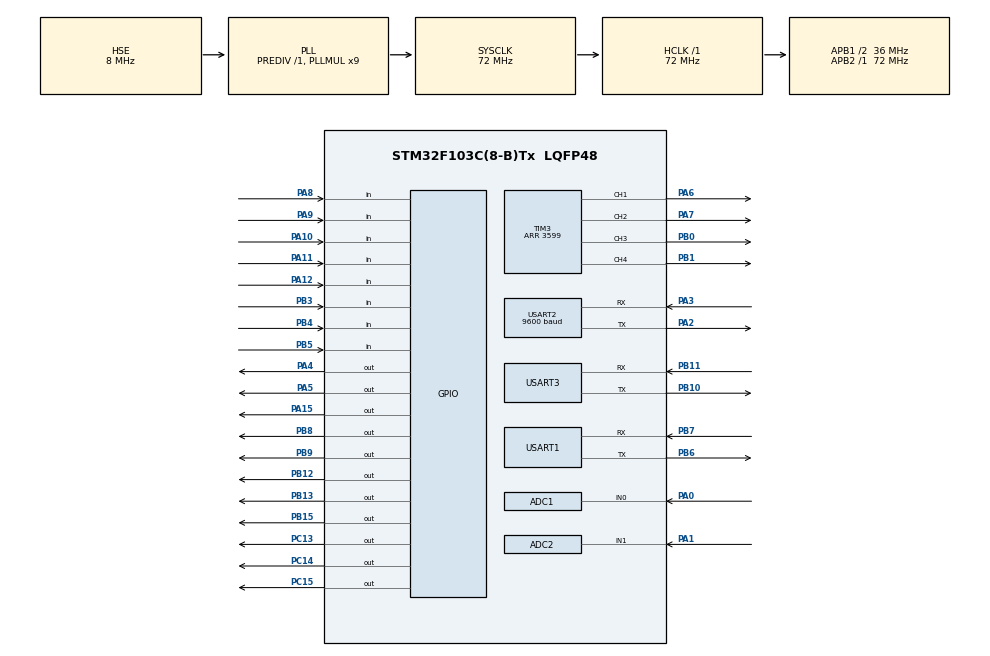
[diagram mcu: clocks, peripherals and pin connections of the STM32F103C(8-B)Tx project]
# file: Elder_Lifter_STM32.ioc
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ADC1.Channel-1\#ChannelRegularConversion=ADC_CHANNEL_0
ADC1.ContinuousConvMode=ENABLE
ADC1.NbrOfConversionFlag=1
ADC1.Rank-1\#ChannelRegularConversion=1
ADC1.SamplingTime-1\#ChannelRegularConversion=ADC_SAMPLETIME_1CYCLE_5
ADC1.master=1
ADC2.Channel-1\#ChannelRegularConversion=ADC_CHANNEL_1
ADC2.ContinuousConvMode=ENABLE
ADC2.NbrOfConversionFlag=1
ADC2.Rank-1\#ChannelRegularConversion=1
ADC2.SamplingTime-1\#ChannelRegularConversion=ADC_SAMPLETIME_1CYCLE_5
Dma.Request0=USART2_RX
Dma.Request1=USART2_TX
Dma.Request2=USART3_RX
Dma.Request3=USART1_RX
Dma.Request4=USART1_TX
Dma.Request5=USART3_TX
Dma.USART1_RX.3.Direction=DMA_PERIPH_TO_MEMORY
Dma.USART1_RX.3.Instance=DMA1_Channel5
Dma.USART1_RX.3.MemDataAlignment=DMA_MDATAALIGN_BYTE
Dma.USART1_RX.3.MemInc=DMA_MINC_ENABLE
Dma.USART1_RX.3.Mode=DMA_NORMAL
Dma.USART1_RX.3.PeriphDataAlignment=DMA_PDATAALIGN_BYTE
Dma.USART1_RX.3.PeriphInc=DMA_PINC_DISABLE
Dma.USART1_RX.3.Priority=DMA_PRIORITY_LOW
Dma.USART1_TX.4.Direction=DMA_MEMORY_TO_PERIPH
Dma.USART1_TX.4.Instance=DMA1_Channel4
Dma.USART1_TX.4.MemDataAlignment=DMA_MDATAALIGN_BYTE
Dma.USART1_TX.4.MemInc=DMA_MINC_ENABLE
Dma.USART1_TX.4.Mode=DMA_NORMAL
Dma.USART1_TX.4.PeriphDataAlignment=DMA_PDATAALIGN_BYTE
Dma.USART1_TX.4.PeriphInc=DMA_PINC_DISABLE
Dma.USART1_TX.4.Priority=DMA_PRIORITY_LOW
Dma.USART2_RX.0.Direction=DMA_PERIPH_TO_MEMORY
Dma.USART2_RX.0.Instance=DMA1_Channel6
Dma.USART2_RX.0.MemDataAlignment=DMA_MDATAALIGN_BYTE
Dma.USART2_RX.0.MemInc=DMA_MINC_ENABLE
Dma.USART2_RX.0.Mode=DMA_NORMAL
Dma.USART2_RX.0.PeriphDataAlignment=DMA_PDATAALIGN_BYTE
Dma.USART2_RX.0.PeriphInc=DMA_PINC_DISABLE
Dma.USART2_RX.0.Priority=DMA_PRIORITY_LOW
Dma.USART2_TX.1.Direction=DMA_MEMORY_TO_PERIPH
Dma.USART2_TX.1.Instance=DMA1_Channel7
Dma.USART2_TX.1.MemDataAlignment=DMA_MDATAALIGN_BYTE
Dma.USART2_TX.1.MemInc=DMA_MINC_ENABLE
Dma.USART2_TX.1.Mode=DMA_NORMAL
Dma.USART2_TX.1.PeriphDataAlignment=DMA_PDATAALIGN_BYTE
Dma.USART2_TX.1.PeriphInc=DMA_PINC_DISABLE
Dma.USART2_TX.1.Priority=DMA_PRIORITY_LOW
Dma.USART3_RX.2.Direction=DMA_PERIPH_TO_MEMORY
Dma.USART3_RX.2.Instance=DMA1_Channel3
Dma.USART3_RX.2.MemDataAlignment=DMA_MDATAALIGN_BYTE
Dma.USART3_RX.2.MemInc=DMA_MINC_ENABLE
Dma.USART3_RX.2.Mode=DMA_NORMAL
Dma.USART3_RX.2.PeriphDataAlignment=DMA_PDATAALIGN_BYTE
Dma.USART3_RX.2.PeriphInc=DMA_PINC_DISABLE
Dma.USART3_RX.2.Priority=DMA_PRIORITY_LOW
Dma.USART3_TX.5.Direction=DMA_MEMORY_TO_PERIPH
Dma.USART3_TX.5.Instance=DMA1_Channel2
Dma.USART3_TX.5.MemDataAlignment=DMA_MDATAALIGN_BYTE
Dma.USART3_TX.5.MemInc=DMA_MINC_ENABLE
Dma.USART3_TX.5.Mode=DMA_NORMAL
Dma.USART3_TX.5.PeriphDataAlignment=DMA_PDATAALIGN_BYTE
Dma.USART3_TX.5.PeriphInc=DMA_PINC_DISABLE
Dma.USART3_TX.5.Priority=DMA_PRIORITY_LOW
Mcu.Family=STM32F1
Mcu.Name=STM32F103C(8-B)Tx
Mcu.Package=LQFP48
NVIC.ADC1_2_IRQn=true\:0\:0\:false\:false\:true\:true\:true\:true
NVIC.DMA1_Channel2_IRQn=true\:0\:0\:false\:false\:true\:false\:true\:true
NVIC.DMA1_Channel3_IRQn=true\:0\:0\:false\:false\:true\:false\:true\:true
NVIC.DMA1_Channel4_IRQn=true\:0\:0\:false\:false\:true\:false\:true\:true
NVIC.DMA1_Channel5_IRQn=true\:0\:0\:false\:false\:true\:false\:true\:true
NVIC.DMA1_Channel6_IRQn=true\:0\:0\:false\:false\:true\:false\:true\:true
NVIC.DMA1_Channel7_IRQn=true\:0\:0\:false\:false\:true\:false\:true\:true
NVIC.PriorityGroup=NVIC_PRIORITYGROUP_4
NVIC.TIM2_IRQn=true\:0\:0\:false\:false\:true\:true\:true\:true
NVIC.USART1_IRQn=true\:0\:0\:false\:false\:true\:true\:true\:true
NVIC.USART2_IRQn=true\:0\:0\:false\:false\:true\:true\:true\:true
NVIC.USART3_IRQn=true\:0\:0\:false\:false\:true\:true\:true\:true
PA0-WKUP.Signal=ADCx_IN0
PA1.Signal=ADCx_IN1
PA10.GPIO_PuPd=GPIO_PULLUP
PA10.Signal=GPIO_Input
PA11.GPIO_PuPd=GPIO_PULLUP
PA11.Signal=GPIO_Input
PA12.GPIO_PuPd=GPIO_PULLUP
PA12.Signal=GPIO_Input
PA13.Mode=Serial_Wire
PA13.Signal=SYS_JTMS-SWDIO
PA14.Mode=Serial_Wire
PA14.Signal=SYS_JTCK-SWCLK
PA15.Signal=GPIO_Output
PA2.Mode=Asynchronous
PA2.Signal=USART2_TX
PA3.Mode=Asynchronous
PA3.Signal=USART2_RX
PA4.Signal=GPIO_Output
PA5.Signal=GPIO_Output
PA6.Signal=S_TIM3_CH1
PA7.Signal=S_TIM3_CH2
PA8.GPIO_PuPd=GPIO_PULLUP
PA8.Signal=GPIO_Input
PA9.GPIO_PuPd=GPIO_PULLUP
PA9.Signal=GPIO_Input
PB0.Signal=S_TIM3_CH3
PB1.Signal=S_TIM3_CH4
PB10.Mode=Asynchronous
PB10.Signal=USART3_TX
PB11.Mode=Asynchronous
PB11.Signal=USART3_RX
PB12.Signal=GPIO_Output
PB13.Signal=GPIO_Output
PB15.Signal=GPIO_Output
PB3.GPIO_PuPd=GPIO_PULLUP
PB3.Signal=GPIO_Input
PB4.GPIO_PuPd=GPIO_PULLUP
PB4.Signal=GPIO_Input
PB5.GPIO_PuPd=GPIO_PULLUP
PB5.Signal=GPIO_Input
PB6.Mode=Asynchronous
PB6.Signal=USART1_TX
PB7.Mode=Asynchronous
PB7.Signal=USART1_RX
PB8.Signal=GPIO_Output
PB9.Signal=GPIO_Output
PC13-TAMPER-RTC.Signal=GPIO_Output
PC14-OSC32_IN.Signal=GPIO_Output
PC15-OSC32_OUT.Signal=GPIO_Output
PD0-OSC_IN.Mode=HSE-External-Oscillator
PD0-OSC_IN.Signal=RCC_OSC_IN
PD1-OSC_OUT.Mode=HSE-External-Oscillator
PD1-OSC_OUT.Signal=RCC_OSC_OUT
ProjectManager.HeapSize=0x200
ProjectManager.StackSize=0x400
ProjectManager.TargetToolchain=STM32CubeIDE
RCC.AHBFreq_Value=72000000
RCC.APB1CLKDivider=RCC_HCLK_DIV2
RCC.APB1Freq_Value=36000000
RCC.APB1TimFreq_Value=72000000
RCC.APB2Freq_Value=72000000
RCC.APB2TimFreq_Value=72000000
RCC.HCLKFreq_Value=72000000
RCC.PLLMUL=RCC_PLL_MUL9
RCC.PLLSourceVirtual=RCC_PLLSOURCE_HSE
RCC.SYSCLKFreq_VALUE=72000000
RCC.SYSCLKSource=RCC_SYSCLKSOURCE_PLLCLK
RCC.USBFreq_Value=48000000
RCC.USBPrescaler=RCC_USBCLKSOURCE_PLL_DIV1_5
SH.ADCx_IN0.0=ADC1_IN0,IN0
SH.ADCx_IN1.0=ADC2_IN1,IN1
SH.ADCx_IN1.1=ADC1_IN1
SH.S_TIM3_CH1.0=TIM3_CH1,PWM Generation1 CH1
SH.S_TIM3_CH2.0=TIM3_CH2,PWM Generation2 CH2
SH.S_TIM3_CH3.0=TIM3_CH3,PWM Generation3 CH3
SH.S_TIM3_CH4.0=TIM3_CH4,PWM Generation4 CH4
TIM2.AutoReloadPreload=TIM_AUTORELOAD_PRELOAD_ENABLE
TIM2.Period=3600
TIM2.Prescaler=1000
TIM3.AutoReloadPreload=TIM_AUTORELOAD_PRELOAD_ENABLE
TIM3.Channel-PWM\ Generation1\ CH1=TIM_CHANNEL_1
TIM3.Channel-PWM\ Generation2\ CH2=TIM_CHANNEL_2
TIM3.Channel-PWM\ Generation3\ CH3=TIM_CHANNEL_3
TIM3.Channel-PWM\ Generation4\ CH4=TIM_CHANNEL_4
TIM3.Period=3599
USART1.VirtualMode=VM_ASYNC
USART2.BaudRate=9600
USART2.VirtualMode=VM_ASYNC
USART3.VirtualMode=VM_ASYNC
VP_TIM2_VS_ClockSourceINT.Mode=Internal
board=custom

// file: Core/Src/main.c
/* USER CODE BEGIN Header */
/**
  ******************************************************************************
  * @file           : main.c
  * @brief          : Main program body
  ******************************************************************************
  * @attention
  *
  * Copyright (c) 2024 STMicroelectronics.
  * All rights reserved.
  *
  * This software is licensed under terms that can be found in the LICENSE file
  * in the root directory of this software component.
  * If no LICENSE file comes with this software, it is provided AS-IS.
  *
  ******************************************************************************
  */
/* USER CODE END Header */
#include "main.h"

/* USER CODE BEGIN Includes */
#include "Lifter_Main.h"
/* USER CODE END Includes */

ADC_HandleTypeDef hadc1;
ADC_HandleTypeDef hadc2;

TIM_HandleTypeDef htim2;
TIM_HandleTypeDef htim3;

UART_HandleTypeDef huart1;
UART_HandleTypeDef huart2;
UART_HandleTypeDef huart3;
DMA_HandleTypeDef hdma_usart1_rx;
DMA_HandleTypeDef hdma_usart1_tx;
DMA_HandleTypeDef hdma_usart2_rx;
DMA_HandleTypeDef hdma_usart2_tx;
DMA_HandleTypeDef hdma_usart3_rx;
DMA_HandleTypeDef hdma_usart3_tx;

void SystemClock_Config(void);
static void MX_GPIO_Init(void);
static void MX_DMA_Init(void);
static void MX_USART2_UART_Init(void);
static void MX_TIM2_Init(void);
static void MX_TIM3_Init(void);
static void MX_USART3_UART_Init(void);
static void MX_USART1_UART_Init(void);
static void MX_ADC1_Init(void);
static void MX_ADC2_Init(void);

int main(void)
{

  /* MCU Configuration--------------------------------------------------------*/

  /* Reset of all peripherals, Initializes the Flash interface and the Systick. */
  HAL_Init();

  /* Configure the system clock */
  SystemClock_Config();

  /* Initialize all configured peripherals */
  MX_GPIO_Init();
  MX_DMA_Init();
  MX_USART2_UART_Init();
  MX_TIM2_Init();
  MX_TIM3_Init();
  MX_USART3_UART_Init();
  MX_USART1_UART_Init();
  MX_ADC1_Init();
  MX_ADC2_Init();
  /* USER CODE BEGIN 2 */
  Lifter_Init();
  /* USER CODE END 2 */

  /* Infinite loop */
  while (1)
  {

    /* USER CODE BEGIN 3 */
	Lifter_Main();
  }
  /* USER CODE END 3 */
}

void SystemClock_Config(void)
{
  RCC_OscInitTypeDef RCC_OscInitStruct = {0};
  RCC_ClkInitTypeDef RCC_ClkInitStruct = {0};
  RCC_PeriphCLKInitTypeDef PeriphClkInit = {0};

  /** Initializes the RCC Oscillators according to the specified parameters
  * in the RCC_OscInitTypeDef structure.
  */
  RCC_OscInitStruct.OscillatorType = RCC_OSCILLATORTYPE_HSE;
  RCC_OscInitStruct.HSEState = RCC_HSE_ON;
  RCC_OscInitStruct.HSEPredivValue = RCC_HSE_PREDIV_DIV1;
  RCC_OscInitStruct.HSIState = RCC_HSI_ON;
  RCC_OscInitStruct.PLL.PLLState = RCC_PLL_ON;
  RCC_OscInitStruct.PLL.PLLSource = RCC_PLLSOURCE_HSE;
  RCC_OscInitStruct.PLL.PLLMUL = RCC_PLL_MUL9;
  if (HAL_RCC_OscConfig(&RCC_OscInitStruct) != HAL_OK)
  {
    Error_Handler();
  }

  /** Initializes the CPU, AHB and APB buses clocks
  */
  RCC_ClkInitStruct.ClockType = RCC_CLOCKTYPE_HCLK|RCC_CLOCKTYPE_SYSCLK
                              |RCC_CLOCKTYPE_PCLK1|RCC_CLOCKTYPE_PCLK2;
  RCC_ClkInitStruct.SYSCLKSource = RCC_SYSCLKSOURCE_PLLCLK;
  RCC_ClkInitStruct.AHBCLKDivider = RCC_SYSCLK_DIV1;
  RCC_ClkInitStruct.APB1CLKDivider = RCC_HCLK_DIV2;
  RCC_ClkInitStruct.APB2CLKDivider = RCC_HCLK_DIV1;

  if (HAL_RCC_ClockConfig(&RCC_ClkInitStruct, FLASH_LATENCY_2) != HAL_OK)
  {
    Error_Handler();
  }
  PeriphClkInit.PeriphClockSelection = RCC_PERIPHCLK_ADC;
  PeriphClkInit.AdcClockSelection = RCC_ADCPCLK2_DIV2;
  if (HAL_RCCEx_PeriphCLKConfig(&PeriphClkInit) != HAL_OK)
  {
    Error_Handler();
  }
}

static void MX_ADC1_Init(void)
{

  ADC_ChannelConfTypeDef sConfig = {0};

  /** Common config
  */
  hadc1.Instance = ADC1;
  hadc1.Init.ScanConvMode = ADC_SCAN_DISABLE;
  hadc1.Init.ContinuousConvMode = ENABLE;
  hadc1.Init.DiscontinuousConvMode = DISABLE;
  hadc1.Init.ExternalTrigConv = ADC_SOFTWARE_START;
  hadc1.Init.DataAlign = ADC_DATAALIGN_RIGHT;
  hadc1.Init.NbrOfConversion = 1;
  if (HAL_ADC_Init(&hadc1) != HAL_OK)
  {
    Error_Handler();
  }

  /** Configure Regular Channel
  */
  sConfig.Channel = ADC_CHANNEL_0;
  sConfig.Rank = ADC_REGULAR_RANK_1;
  sConfig.SamplingTime = ADC_SAMPLETIME_1CYCLE_5;
  if (HAL_ADC_ConfigChannel(&hadc1, &sConfig) != HAL_OK)
  {
    Error_Handler();
  }

}

static void MX_ADC2_Init(void)
{

  ADC_ChannelConfTypeDef sConfig = {0};

  /** Common config
  */
  hadc2.Instance = ADC2;
  hadc2.Init.ScanConvMode = ADC_SCAN_DISABLE;
  hadc2.Init.ContinuousConvMode = ENABLE;
  hadc2.Init.DiscontinuousConvMode = DISABLE;
  hadc2.Init.ExternalTrigConv = ADC_SOFTWARE_START;
  hadc2.Init.DataAlign = ADC_DATAALIGN_RIGHT;
  hadc2.Init.NbrOfConversion = 1;
  if (HAL_ADC_Init(&hadc2) != HAL_OK)
  {
    Error_Handler();
  }

  /** Configure Regular Channel
  */
  sConfig.Channel = ADC_CHANNEL_1;
  sConfig.Rank = ADC_REGULAR_RANK_1;
  sConfig.SamplingTime = ADC_SAMPLETIME_1CYCLE_5;
  if (HAL_ADC_ConfigChannel(&hadc2, &sConfig) != HAL_OK)
  {
    Error_Handler();
  }

}

static void MX_TIM2_Init(void)
{

  TIM_ClockConfigTypeDef sClockSourceConfig = {0};
  TIM_MasterConfigTypeDef sMasterConfig = {0};

  htim2.Instance = TIM2;
  htim2.Init.Prescaler = 1000;
  htim2.Init.CounterMode = TIM_COUNTERMODE_UP;
  htim2.Init.Period = 3600;
  htim2.Init.ClockDivision = TIM_CLOCKDIVISION_DIV1;
  htim2.Init.AutoReloadPreload = TIM_AUTORELOAD_PRELOAD_ENABLE;
  if (HAL_TIM_Base_Init(&htim2) != HAL_OK)
  {
    Error_Handler();
  }
  sClockSourceConfig.ClockSource = TIM_CLOCKSOURCE_INTERNAL;
  if (HAL_TIM_ConfigClockSource(&htim2, &sClockSourceConfig) != HAL_OK)
  {
    Error_Handler();
  }
  sMasterConfig.MasterOutputTrigger = TIM_TRGO_RESET;
  sMasterConfig.MasterSlaveMode = TIM_MASTERSLAVEMODE_DISABLE;
  if (HAL_TIMEx_MasterConfigSynchronization(&htim2, &sMasterConfig) != HAL_OK)
  {
    Error_Handler();
  }

}

static void MX_TIM3_Init(void)
{

  TIM_MasterConfigTypeDef sMasterConfig = {0};
  TIM_OC_InitTypeDef sConfigOC = {0};

  htim3.Instance = TIM3;
  htim3.Init.Prescaler = 0;
  htim3.Init.CounterMode = TIM_COUNTERMODE_UP;
  htim3.Init.Period = 3599;
  htim3.Init.ClockDivision = TIM_CLOCKDIVISION_DIV1;
  htim3.Init.AutoReloadPreload = TIM_AUTORELOAD_PRELOAD_ENABLE;
  if (HAL_TIM_PWM_Init(&htim3) != HAL_OK)
  {
    Error_Handler();
  }
  sMasterConfig.MasterOutputTrigger = TIM_TRGO_RESET;
  sMasterConfig.MasterSlaveMode = TIM_MASTERSLAVEMODE_DISABLE;
  if (HAL_TIMEx_MasterConfigSynchronization(&htim3, &sMasterConfig) != HAL_OK)
  {
    Error_Handler();
  }
  sConfigOC.OCMode = TIM_OCMODE_PWM1;
  sConfigOC.Pulse = 0;
  sConfigOC.OCPolarity = TIM_OCPOLARITY_HIGH;
  sConfigOC.OCFastMode = TIM_OCFAST_DISABLE;
  if (HAL_TIM_PWM_ConfigChannel(&htim3, &sConfigOC, TIM_CHANNEL_1) != HAL_OK)
  {
    Error_Handler();
  }
  if (HAL_TIM_PWM_ConfigChannel(&htim3, &sConfigOC, TIM_CHANNEL_2) != HAL_OK)
  {
    Error_Handler();
  }
  if (HAL_TIM_PWM_ConfigChannel(&htim3, &sConfigOC, TIM_CHANNEL_3) != HAL_OK)
  {
    Error_Handler();
  }
  if (HAL_TIM_PWM_ConfigChannel(&htim3, &sConfigOC, TIM_CHANNEL_4) != HAL_OK)
  {
    Error_Handler();
  }
  HAL_TIM_MspPostInit(&htim3);

}

static void MX_USART1_UART_Init(void)
{

  huart1.Instance = USART1;
  huart1.Init.BaudRate = 115200;
  huart1.Init.WordLength = UART_WORDLENGTH_8B;
  huart1.Init.StopBits = UART_STOPBITS_1;
  huart1.Init.Parity = UART_PARITY_NONE;
  huart1.Init.Mode = UART_MODE_TX_RX;
  huart1.Init.HwFlowCtl = UART_HWCONTROL_NONE;
  huart1.Init.OverSampling = UART_OVERSAMPLING_16;
  if (HAL_UART_Init(&huart1) != HAL_OK)
  {
    Error_Handler();
  }

}

static void MX_USART2_UART_Init(void)
{

  huart2.Instance = USART2;
  huart2.Init.BaudRate = 9600;
  huart2.Init.WordLength = UART_WORDLENGTH_8B;
  huart2.Init.StopBits = UART_STOPBITS_1;
  huart2.Init.Parity = UART_PARITY_NONE;
  huart2.Init.Mode = UART_MODE_TX_RX;
  huart2.Init.HwFlowCtl = UART_HWCONTROL_NONE;
  huart2.Init.OverSampling = UART_OVERSAMPLING_16;
  if (HAL_UART_Init(&huart2) != HAL_OK)
  {
    Error_Handler();
  }

}

static void MX_USART3_UART_Init(void)
{

  huart3.Instance = USART3;
  huart3.Init.BaudRate = 115200;
  huart3.Init.WordLength = UART_WORDLENGTH_8B;
  huart3.Init.StopBits = UART_STOPBITS_1;
  huart3.Init.Parity = UART_PARITY_NONE;
  huart3.Init.Mode = UART_MODE_TX_RX;
  huart3.Init.HwFlowCtl = UART_HWCONTROL_NONE;
  huart3.Init.OverSampling = UART_OVERSAMPLING_16;
  if (HAL_UART_Init(&huart3) != HAL_OK)
  {
    Error_Handler();
  }

}

static void MX_DMA_Init(void)
{

  /* DMA controller clock enable */
  __HAL_RCC_DMA1_CLK_ENABLE();

  /* DMA interrupt init */
  /* DMA1_Channel2_IRQn interrupt configuration */
  HAL_NVIC_SetPriority(DMA1_Channel2_IRQn, 0, 0);
  HAL_NVIC_EnableIRQ(DMA1_Channel2_IRQn);
  /* DMA1_Channel3_IRQn interrupt configuration */
  HAL_NVIC_SetPriority(DMA1_Channel3_IRQn, 0, 0);
  HAL_NVIC_EnableIRQ(DMA1_Channel3_IRQn);
  /* DMA1_Channel4_IRQn interrupt configuration */
  HAL_NVIC_SetPriority(DMA1_Channel4_IRQn, 0, 0);
  HAL_NVIC_EnableIRQ(DMA1_Channel4_IRQn);
  /* DMA1_Channel5_IRQn interrupt configuration */
  HAL_NVIC_SetPriority(DMA1_Channel5_IRQn, 0, 0);
  HAL_NVIC_EnableIRQ(DMA1_Channel5_IRQn);
  /* DMA1_Channel6_IRQn interrupt configuration */
  HAL_NVIC_SetPriority(DMA1_Channel6_IRQn, 0, 0);
  HAL_NVIC_EnableIRQ(DMA1_Channel6_IRQn);
  /* DMA1_Channel7_IRQn interrupt configuration */
  HAL_NVIC_SetPriority(DMA1_Channel7_IRQn, 0, 0);
  HAL_NVIC_EnableIRQ(DMA1_Channel7_IRQn);

}

static void MX_GPIO_Init(void)
{
  GPIO_InitTypeDef GPIO_InitStruct = {0};

  /* GPIO Ports Clock Enable */
  __HAL_RCC_GPIOC_CLK_ENABLE();
  __HAL_RCC_GPIOD_CLK_ENABLE();
  __HAL_RCC_GPIOA_CLK_ENABLE();
  __HAL_RCC_GPIOB_CLK_ENABLE();

  /*Configure GPIO pin Output Level */
  HAL_GPIO_WritePin(GPIOC, GPIO_PIN_13|GPIO_PIN_14|GPIO_PIN_15, GPIO_PIN_RESET);

  /*Configure GPIO pin Output Level */
  HAL_GPIO_WritePin(GPIOA, GPIO_PIN_4|GPIO_PIN_5|GPIO_PIN_15, GPIO_PIN_RESET);

  /*Configure GPIO pin Output Level */
  HAL_GPIO_WritePin(GPIOB, GPIO_PIN_12|GPIO_PIN_13|GPIO_PIN_15|GPIO_PIN_8
                          |GPIO_PIN_9, GPIO_PIN_RESET);

  /*Configure GPIO pins : PC13 PC14 PC15 */
  GPIO_InitStruct.Pin = GPIO_PIN_13|GPIO_PIN_14|GPIO_PIN_15;
  GPIO_InitStruct.Mode = GPIO_MODE_OUTPUT_PP;
  GPIO_InitStruct.Pull = GPIO_NOPULL;
  GPIO_InitStruct.Speed = GPIO_SPEED_FREQ_LOW;
  HAL_GPIO_Init(GPIOC, &GPIO_InitStruct);

  /*Configure GPIO pins : PA4 PA5 PA15 */
  GPIO_InitStruct.Pin = GPIO_PIN_4|GPIO_PIN_5|GPIO_PIN_15;
  GPIO_InitStruct.Mode = GPIO_MODE_OUTPUT_PP;
  GPIO_InitStruct.Pull = GPIO_NOPULL;
  GPIO_InitStruct.Speed = GPIO_SPEED_FREQ_LOW;
  HAL_GPIO_Init(GPIOA, &GPIO_InitStruct);

  /*Configure GPIO pins : PB12 PB13 PB15 PB8
                           PB9 */
  GPIO_InitStruct.Pin = GPIO_PIN_12|GPIO_PIN_13|GPIO_PIN_15|GPIO_PIN_8
                          |GPIO_PIN_9;
  GPIO_InitStruct.Mode = GPIO_MODE_OUTPUT_PP;
  GPIO_InitStruct.Pull = GPIO_NOPULL;
  GPIO_InitStruct.Speed = GPIO_SPEED_FREQ_LOW;
  HAL_GPIO_Init(GPIOB, &GPIO_InitStruct);

  /*Configure GPIO pins : PA8 PA9 PA10 PA11
                           PA12 */
  GPIO_InitStruct.Pin = GPIO_PIN_8|GPIO_PIN_9|GPIO_PIN_10|GPIO_PIN_11
                          |GPIO_PIN_12;
  GPIO_InitStruct.Mode = GPIO_MODE_INPUT;
  GPIO_InitStruct.Pull = GPIO_PULLUP;
  HAL_GPIO_Init(GPIOA, &GPIO_InitStruct);

  /*Configure GPIO pins : PB3 PB4 PB5 */
  GPIO_InitStruct.Pin = GPIO_PIN_3|GPIO_PIN_4|GPIO_PIN_5;
  GPIO_InitStruct.Mode = GPIO_MODE_INPUT;
  GPIO_InitStruct.Pull = GPIO_PULLUP;
  HAL_GPIO_Init(GPIOB, &GPIO_InitStruct);

}

void Error_Handler(void)
{
  __disable_irq();
  while (1)
  {
  }
}
